AUTOSAR XML (schema 00046)
package /RunnableLab
  sender receiver interface SRIF_Throttle
    data CMD: type=uint32
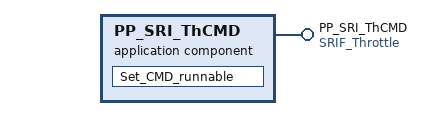
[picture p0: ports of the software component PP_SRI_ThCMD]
  application sw component type PP_SRI_ThCMD
    provide port PP_SRI_ThCMD: provided-interface=SRIF_Throttle
    behavior ThController_Beh
      runnable Set_CMD_runnable
        data-write-access:
          access CMD_Data: accessed-variable=PP_SRI_ThCMD.CMD
